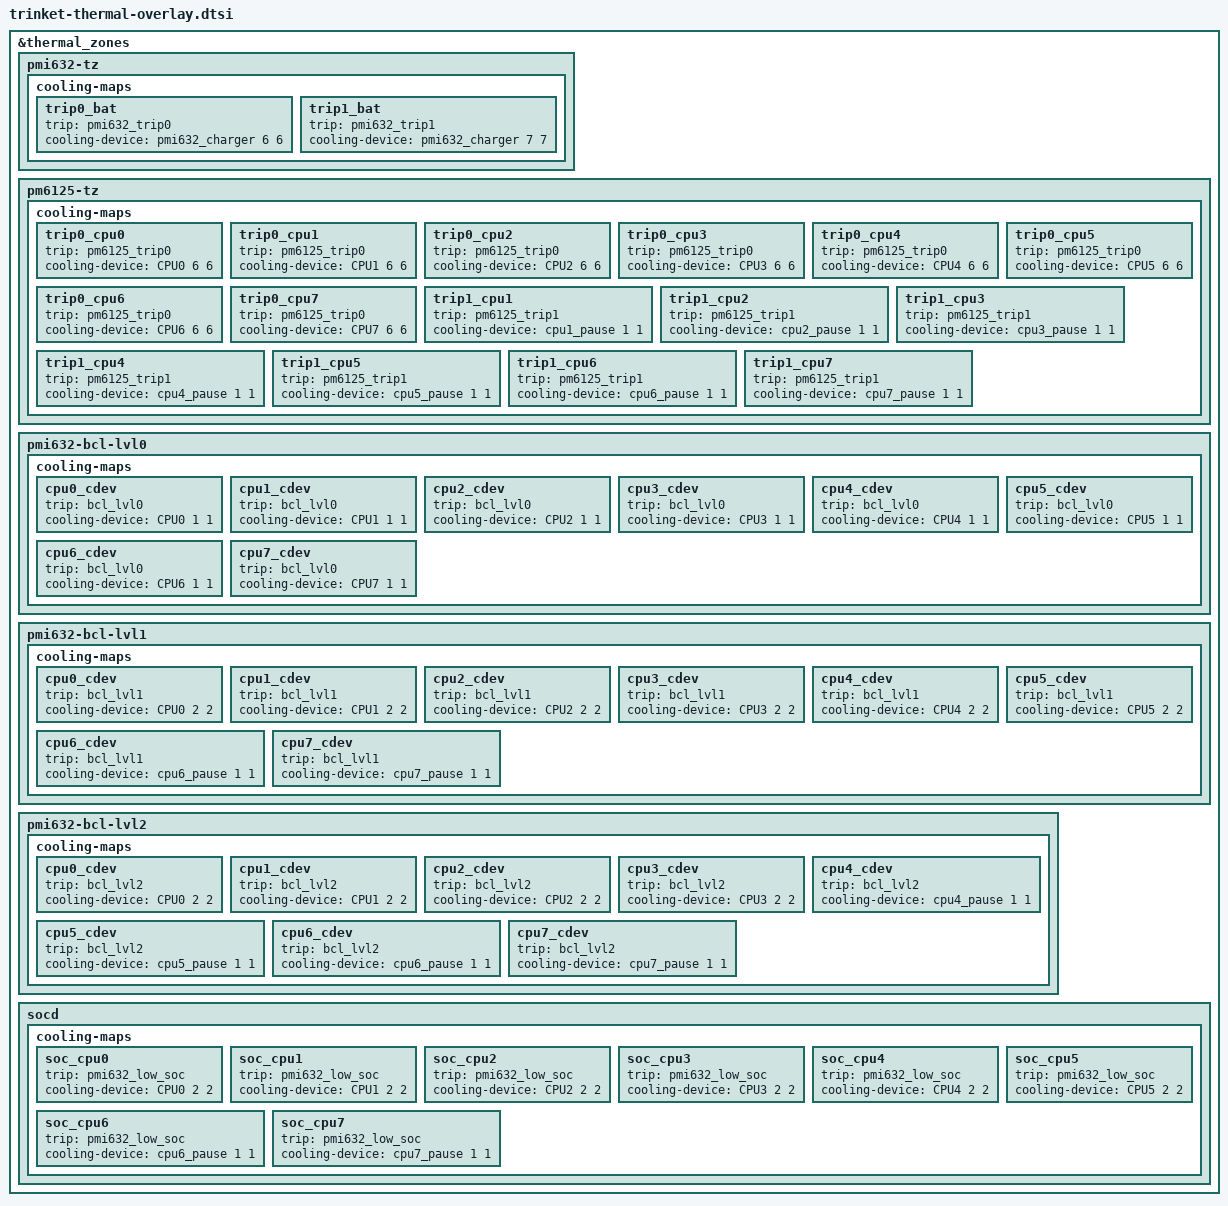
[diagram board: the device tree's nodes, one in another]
#include <dt-bindings/thermal/thermal.h>

&thermal_zones {
	pmi632-tz {
		cooling-maps {
			trip0_bat {
				trip = <&pmi632_trip0>;
				cooling-device = <&pmi632_charger 6 6>;
			};

			trip1_bat {
				trip = <&pmi632_trip1>;
				cooling-device = <&pmi632_charger 7 7>;
			};
		};
	};

	pm6125-tz {
		cooling-maps {
			trip0_cpu0 {
				trip = <&pm6125_trip0>;
				cooling-device = <&CPU0 6 6>;
			};

			trip0_cpu1 {
				trip = <&pm6125_trip0>;
				cooling-device = <&CPU1 6 6>;
			};

			trip0_cpu2 {
				trip = <&pm6125_trip0>;
				cooling-device = <&CPU2 6 6>;
			};

			trip0_cpu3 {
				trip = <&pm6125_trip0>;
				cooling-device = <&CPU3 6 6>;
			};

			trip0_cpu4 {
				trip = <&pm6125_trip0>;
				cooling-device = <&CPU4 6 6>;
			};

			trip0_cpu5 {
				trip = <&pm6125_trip0>;
				cooling-device = <&CPU5 6 6>;
			};

			trip0_cpu6 {
				trip = <&pm6125_trip0>;
				cooling-device = <&CPU6 6 6>;
			};

			trip0_cpu7 {
				trip = <&pm6125_trip0>;
				cooling-device = <&CPU7 6 6>;
			};

			trip1_cpu1 {
				trip = <&pm6125_trip1>;
				cooling-device = <&cpu1_pause 1 1>;
			};

			trip1_cpu2 {
				trip = <&pm6125_trip1>;
				cooling-device = <&cpu2_pause 1 1>;
			};

			trip1_cpu3 {
				trip = <&pm6125_trip1>;
				cooling-device = <&cpu3_pause 1 1>;
			};

			trip1_cpu4 {
				trip = <&pm6125_trip1>;
				cooling-device = <&cpu4_pause 1 1>;
			};

			trip1_cpu5 {
				trip = <&pm6125_trip1>;
				cooling-device = <&cpu5_pause 1 1>;
			};

			trip1_cpu6 {
				trip = <&pm6125_trip1>;
				cooling-device = <&cpu6_pause 1 1>;
			};

			trip1_cpu7 {
				trip = <&pm6125_trip1>;
				cooling-device = <&cpu7_pause 1 1>;
			};
		};
	};

	pmi632-bcl-lvl0 {
		cooling-maps {
			cpu0_cdev {
				trip = <&bcl_lvl0>;
				cooling-device = <&CPU0 1 1>;
			};

			cpu1_cdev {
				trip = <&bcl_lvl0>;
				cooling-device = <&CPU1 1 1>;
			};

			cpu2_cdev {
				trip = <&bcl_lvl0>;
				cooling-device = <&CPU2 1 1>;
			};

			cpu3_cdev {
				trip = <&bcl_lvl0>;
				cooling-device = <&CPU3 1 1>;
			};

			cpu4_cdev {
				trip = <&bcl_lvl0>;
				cooling-device = <&CPU4 1 1>;
			};

			cpu5_cdev {
				trip = <&bcl_lvl0>;
				cooling-device = <&CPU5 1 1>;
			};

			cpu6_cdev {
				trip = <&bcl_lvl0>;
				cooling-device = <&CPU6 1 1>;
			};

			cpu7_cdev {
				trip = <&bcl_lvl0>;
				cooling-device = <&CPU7 1 1>;
			};
		};
	};

	pmi632-bcl-lvl1 {
		cooling-maps {
			cpu0_cdev {
				trip = <&bcl_lvl1>;
				cooling-device = <&CPU0 2 2>;
			};

			cpu1_cdev {
				trip = <&bcl_lvl1>;
				cooling-device = <&CPU1 2 2>;
			};

			cpu2_cdev {
				trip = <&bcl_lvl1>;
				cooling-device = <&CPU2 2 2>;
			};

			cpu3_cdev {
				trip = <&bcl_lvl1>;
				cooling-device = <&CPU3 2 2>;
			};

			cpu4_cdev {
				trip = <&bcl_lvl1>;
				cooling-device = <&CPU4 2 2>;
			};

			cpu5_cdev {
				trip = <&bcl_lvl1>;
				cooling-device = <&CPU5 2 2>;
			};

			cpu6_cdev {
				trip = <&bcl_lvl1>;
				cooling-device = <&cpu6_pause 1 1>;
			};

			cpu7_cdev {
				trip = <&bcl_lvl1>;
				cooling-device = <&cpu7_pause 1 1>;
			};
		};
	};

	pmi632-bcl-lvl2 {
		cooling-maps {
			cpu0_cdev {
				trip = <&bcl_lvl2>;
				cooling-device = <&CPU0 2 2>;
			};

			cpu1_cdev {
				trip = <&bcl_lvl2>;
				cooling-device = <&CPU1 2 2>;
			};

			cpu2_cdev {
				trip = <&bcl_lvl2>;
				cooling-device = <&CPU2 2 2>;
			};

			cpu3_cdev {
				trip = <&bcl_lvl2>;
				cooling-device = <&CPU3 2 2>;
			};

			cpu4_cdev {
				trip = <&bcl_lvl2>;
				cooling-device = <&cpu4_pause 1 1>;
			};

			cpu5_cdev {
				trip = <&bcl_lvl2>;
				cooling-device = <&cpu5_pause 1 1>;
			};

			cpu6_cdev {
				trip = <&bcl_lvl2>;
				cooling-device = <&cpu6_pause 1 1>;
			};

			cpu7_cdev {
				trip = <&bcl_lvl2>;
				cooling-device = <&cpu7_pause 1 1>;
			};
		};
	};

	socd {
		cooling-maps {
			soc_cpu0 {
				trip = <&pmi632_low_soc>;
				cooling-device = <&CPU0 2 2>;
			};

			soc_cpu1 {
				trip = <&pmi632_low_soc>;
				cooling-device = <&CPU1 2 2>;
			};

			soc_cpu2 {
				trip = <&pmi632_low_soc>;
				cooling-device = <&CPU2 2 2>;
			};

			soc_cpu3 {
				trip = <&pmi632_low_soc>;
				cooling-device = <&CPU3 2 2>;
			};

			soc_cpu4 {
				trip = <&pmi632_low_soc>;
				cooling-device = <&CPU4 2 2>;
			};

			soc_cpu5 {
				trip = <&pmi632_low_soc>;
				cooling-device = <&CPU5 2 2>;
			};

			soc_cpu6 {
				trip = <&pmi632_low_soc>;
				cooling-device = <&cpu6_pause 1 1>;
			};

			soc_cpu7 {
				trip = <&pmi632_low_soc>;
				cooling-device = <&cpu7_pause 1 1>;
			};
		};
	};
};

